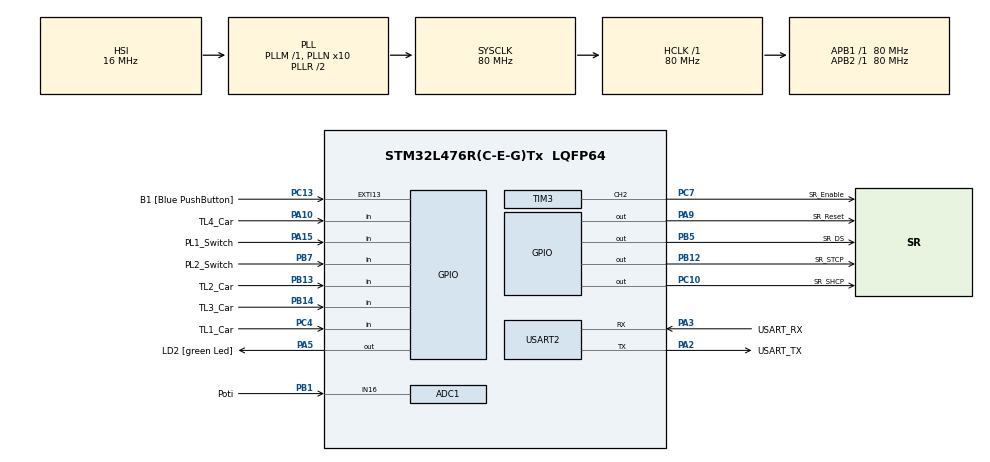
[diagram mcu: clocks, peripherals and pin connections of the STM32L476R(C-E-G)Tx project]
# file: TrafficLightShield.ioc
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ADC1.Channel-0\#ChannelRegularConversion=ADC_CHANNEL_16
ADC1.ClockPrescaler=ADC_CLOCK_SYNC_PCLK_DIV4
ADC1.ContinuousConvMode=ENABLE
ADC1.NbrOfConversionFlag=1
ADC1.OffsetNumber-0\#ChannelRegularConversion=ADC_OFFSET_NONE
ADC1.Rank-0\#ChannelRegularConversion=1
ADC1.SamplingTime-0\#ChannelRegularConversion=ADC_SAMPLETIME_247CYCLES_5
ADC1.master=1
Mcu.Family=STM32L4
Mcu.Name=STM32L476R(C-E-G)Tx
Mcu.Package=LQFP64
NVIC.PriorityGroup=NVIC_PRIORITYGROUP_4
PA10.GPIO_Label=TL4_Car
PA10.Signal=GPIO_Input
PA14\ (JTCK-SWCLK).GPIO_Label=TCK
PA14\ (JTCK-SWCLK).Signal=SYS_JTCK-SWCLK
PA15\ (JTDI).GPIO_Label=PL1_Switch
PA15\ (JTDI).Signal=GPIO_Input
PA2.GPIO_Label=USART_TX
PA2.GPIO_Mode=GPIO_MODE_AF_PP
PA2.GPIO_PuPd=GPIO_NOPULL
PA2.GPIO_Speed=GPIO_SPEED_FREQ_VERY_HIGH
PA2.Mode=Asynchronous
PA2.Signal=USART2_TX
PA3.GPIO_Label=USART_RX
PA3.GPIO_Mode=GPIO_MODE_AF_PP
PA3.GPIO_PuPd=GPIO_NOPULL
PA3.GPIO_Speed=GPIO_SPEED_FREQ_VERY_HIGH
PA3.Mode=Asynchronous
PA3.Signal=USART2_RX
PA5.GPIO_Label=LD2 [green Led]
PA5.GPIO_ModeDefaultOutputPP=GPIO_MODE_OUTPUT_PP
PA5.GPIO_PuPd=GPIO_NOPULL
PA5.GPIO_Speed=GPIO_SPEED_FREQ_LOW
PA5.Signal=GPIO_Output
PA9.GPIO_Label=SR_Reset
PA9.Signal=GPIO_Output
PB1.GPIO_Label=Poti
PB1.Signal=ADCx_IN16
PB12.GPIO_Label=SR_STCP
PB12.Signal=GPIO_Output
PB13.GPIO_Label=TL2_Car
PB13.Signal=GPIO_Input
PB14.GPIO_Label=TL3_Car
PB14.Signal=GPIO_Input
PB3\ (JTDO-TRACESWO).GPIO_Label=SWO
PB3\ (JTDO-TRACESWO).Signal=SYS_JTDO-SWO
PB5.GPIO_Label=SR_DS
PB5.Signal=GPIO_Output
PB7.GPIO_Label=PL2_Switch
PB7.Signal=GPIO_Input
PC10.GPIO_Label=SR_SHCP
PC10.Signal=GPIO_Output
PC13.GPIO_Label=B1 [Blue PushButton]
PC13.GPIO_ModeDefaultEXTI=GPIO_MODE_IT_FALLING
PC13.GPIO_PuPd=GPIO_NOPULL
PC13.Signal=GPXTI13
PC14-OSC32_IN\ (PC14).Mode=LSE-External-Oscillator
PC14-OSC32_IN\ (PC14).Signal=RCC_OSC32_IN
PC15-OSC32_OUT\ (PC15).Mode=LSE-External-Oscillator
PC15-OSC32_OUT\ (PC15).Signal=RCC_OSC32_OUT
PC4.GPIO_Label=TL1_Car
PC4.Signal=GPIO_Input
PC7.GPIO_Label=SR_Enable
PC7.Signal=S_TIM3_CH2
PH0-OSC_IN\ (PH0).Signal=RCC_OSC_IN
PH1-OSC_OUT\ (PH1).Signal=RCC_OSC_OUT
ProjectManager.HeapSize=0x200
ProjectManager.StackSize=0x400
ProjectManager.TargetToolchain=STM32CubeIDE
RCC.ADCFreq_Value=64000000
RCC.AHBFreq_Value=80000000
RCC.APB1Freq_Value=80000000
RCC.APB1TimFreq_Value=80000000
RCC.APB2Freq_Value=80000000
RCC.APB2TimFreq_Value=80000000
RCC.CortexFreq_Value=80000000
RCC.HCLKFreq_Value=80000000
RCC.HSE_VALUE=8000000
RCC.HSI_VALUE=16000000
RCC.MSI_VALUE=4000000
RCC.PLLN=10
RCC.PLLSourceVirtual=RCC_PLLSOURCE_HSI
RCC.PREFETCH_ENABLE=1
RCC.SYSCLKFreq_VALUE=80000000
RCC.SYSCLKSource=RCC_SYSCLKSOURCE_PLLCLK
RCC.USBFreq_Value=64000000
RCC.VCOOutputFreq_Value=160000000
SH.ADCx_IN16.0=ADC1_IN16,IN16-Single-Ended
SH.S_TIM3_CH2.0=TIM3_CH2,PWM Generation2 CH2
TIM3.AutoReloadPreload=TIM_AUTORELOAD_PRELOAD_ENABLE
TIM3.Channel-PWM\ Generation2\ CH2=TIM_CHANNEL_2
TIM3.Period=999
TIM3.Prescaler=79
TIM3.Pulse-PWM\ Generation2\ CH2=999
USART2.VirtualMode-Asynchronous=VM_ASYNC
VP_TIM3_VS_ClockSourceINT.Mode=Internal
board=NUCLEO-L476RG

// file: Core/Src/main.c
/* USER CODE BEGIN Header */
/**
  ******************************************************************************
  * @file           : main.c
  * @brief          : Main program body
  ******************************************************************************
  * @attention
  *
  * Copyright (c) 2025 STMicroelectronics.
  * All rights reserved.
  *
  * This software is licensed under terms that can be found in the LICENSE file
  * in the root directory of this software component.
  * If no LICENSE file comes with this software, it is provided AS-IS.
  *
  ******************************************************************************
  */
/* USER CODE END Header */
#include "main.h"
#include "adc.h"
#include "tim.h"
#include "usart.h"
#include "gpio.h"

/* USER CODE BEGIN Includes */
#include "shift_register.h"
/* USER CODE END Includes */

void SystemClock_Config(void);

int main(void)
{

  /* MCU Configuration--------------------------------------------------------*/

  /* Reset of all peripherals, Initializes the Flash interface and the Systick. */
  HAL_Init();

  /* Configure the system clock */
  SystemClock_Config();

  /* Initialize all configured peripherals */
  MX_GPIO_Init();
  MX_USART2_UART_Init();
  MX_ADC1_Init();
  MX_TIM3_Init();
  /* USER CODE BEGIN 2 */

  // Start PWM on TIM3 CH2 for LED brightness control (OE# pin)
  HAL_TIM_PWM_Start(&htim3, TIM_CHANNEL_2);
  // Set to 0% duty cycle for max brightness (OE# is active LOW: 0% = LOW = enabled)
  __HAL_TIM_SET_COMPARE(&htim3, TIM_CHANNEL_2, 0);

  // Initialize shift registers
  ShiftReg_Init();

  // Run LED test sequence (comment out when not testing hardware)
  // ShiftReg_Test();

  /* USER CODE END 2 */

  /* Infinite loop */
  while (1)
  {

    /* USER CODE BEGIN 3 */

    // TODO: Implement traffic light control logic here

  }
  /* USER CODE END 3 */
}

void SystemClock_Config(void)
{
  RCC_OscInitTypeDef RCC_OscInitStruct = {0};
  RCC_ClkInitTypeDef RCC_ClkInitStruct = {0};

  /** Configure the main internal regulator output voltage
  */
  if (HAL_PWREx_ControlVoltageScaling(PWR_REGULATOR_VOLTAGE_SCALE1) != HAL_OK)
  {
    Error_Handler();
  }

  /** Initializes the RCC Oscillators according to the specified parameters
  * in the RCC_OscInitTypeDef structure.
  */
  RCC_OscInitStruct.OscillatorType = RCC_OSCILLATORTYPE_HSI;
  RCC_OscInitStruct.HSIState = RCC_HSI_ON;
  RCC_OscInitStruct.HSICalibrationValue = RCC_HSICALIBRATION_DEFAULT;
  RCC_OscInitStruct.PLL.PLLState = RCC_PLL_ON;
  RCC_OscInitStruct.PLL.PLLSource = RCC_PLLSOURCE_HSI;
  RCC_OscInitStruct.PLL.PLLM = 1;
  RCC_OscInitStruct.PLL.PLLN = 10;
  RCC_OscInitStruct.PLL.PLLP = RCC_PLLP_DIV7;
  RCC_OscInitStruct.PLL.PLLQ = RCC_PLLQ_DIV2;
  RCC_OscInitStruct.PLL.PLLR = RCC_PLLR_DIV2;
  if (HAL_RCC_OscConfig(&RCC_OscInitStruct) != HAL_OK)
  {
    Error_Handler();
  }

  /** Initializes the CPU, AHB and APB buses clocks
  */
  RCC_ClkInitStruct.ClockType = RCC_CLOCKTYPE_HCLK|RCC_CLOCKTYPE_SYSCLK
                              |RCC_CLOCKTYPE_PCLK1|RCC_CLOCKTYPE_PCLK2;
  RCC_ClkInitStruct.SYSCLKSource = RCC_SYSCLKSOURCE_PLLCLK;
  RCC_ClkInitStruct.AHBCLKDivider = RCC_SYSCLK_DIV1;
  RCC_ClkInitStruct.APB1CLKDivider = RCC_HCLK_DIV1;
  RCC_ClkInitStruct.APB2CLKDivider = RCC_HCLK_DIV1;

  if (HAL_RCC_ClockConfig(&RCC_ClkInitStruct, FLASH_LATENCY_4) != HAL_OK)
  {
    Error_Handler();
  }
}

void Error_Handler(void)
{
  __disable_irq();
  while (1)
  {
  }
}
